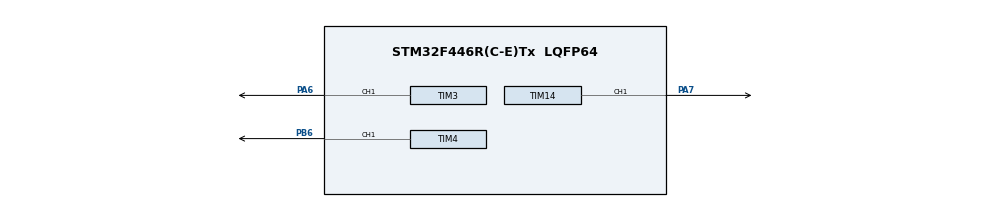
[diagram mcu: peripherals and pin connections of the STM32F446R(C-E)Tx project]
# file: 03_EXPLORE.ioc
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Mcu.Family=STM32F4
Mcu.Name=STM32F446R(C-E)Tx
Mcu.Package=LQFP64
NVIC.PriorityGroup=NVIC_PRIORITYGROUP_4
NVIC.TIM1_UP_TIM10_IRQn=true\:0\:0\:false\:false\:true\:true\:true\:true
PA6.Signal=S_TIM3_CH1
PA7.Signal=S_TIM14_CH1
PB6.Signal=S_TIM4_CH1
ProjectManager.HeapSize=0x200
ProjectManager.StackSize=0x400
ProjectManager.TargetToolchain=SW4STM32
RCC.CortexFreq_Value=16000000
RCC.USBFreq_Value=96000000
RCC.VCOOutputFreq_Value=192000000
SH.S_TIM14_CH1.0=TIM14_CH1,PWM Generation1 CH1
SH.S_TIM3_CH1.0=TIM3_CH1,PWM Generation1 CH1
SH.S_TIM4_CH1.0=TIM4_CH1,PWM Generation1 CH1
TIM1.Period=9
TIM1.Prescaler=15999
TIM14.Channel=TIM_CHANNEL_1
TIM14.Period=999
TIM14.Prescaler=159
TIM3.Channel-PWM\ Generation1\ CH1=TIM_CHANNEL_1
TIM3.Period=999
TIM3.Prescaler=159
TIM4.Channel-PWM\ Generation1\ CH1=TIM_CHANNEL_1
TIM4.Period=999
TIM4.Prescaler=159
VP_TIM14_VS_ClockSourceINT.Mode=Enable_Timer
VP_TIM1_VS_ClockSourceINT.Mode=Internal
VP_TIM3_VS_ClockSourceINT.Mode=Internal
VP_TIM4_VS_ClockSourceINT.Mode=Internal
board=custom

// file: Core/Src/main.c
/* USER CODE BEGIN Header */
/**
  ******************************************************************************
  * @file           : main.c
  * @brief          : Main program body
  ******************************************************************************
  * @attention
  *
  * Copyright (c) 2025 STMicroelectronics.
  * All rights reserved.
  *
  * This software is licensed under terms that can be found in the LICENSE file
  * in the root directory of this software component.
  * If no LICENSE file comes with this software, it is provided AS-IS.
  *
  ******************************************************************************
  */
/* USER CODE END Header */
#include "main.h"

 TIM_HandleTypeDef htim1;
TIM_HandleTypeDef htim3;
TIM_HandleTypeDef htim4;
TIM_HandleTypeDef htim14;

/* USER CODE BEGIN PV */
#define FADE_STEPS   500  // 每个颜色渐变持续 2 秒（10ms 步进 × 200）

static uint16_t fade_step = 0;
static uint8_t fade_phase = 0;  // 0: R->G, 1: G->B, 2: B->R

uint32_t pwm_arr = 1000; // 对应你设置的 Period + 1
/* USER CODE END PV */

void SystemClock_Config(void);
static void MX_GPIO_Init(void);
static void MX_TIM1_Init(void);
static void MX_TIM3_Init(void);
static void MX_TIM4_Init(void);
static void MX_TIM14_Init(void);

int main(void)
{

  /* MCU Configuration--------------------------------------------------------*/

  /* Reset of all peripherals, Initializes the Flash interface and the Systick. */
  HAL_Init();

  /* Configure the system clock */
  SystemClock_Config();

  /* Initialize all configured peripherals */
  MX_GPIO_Init();
  MX_TIM1_Init();
  MX_TIM3_Init();
  MX_TIM4_Init();
  MX_TIM14_Init();
  /* USER CODE BEGIN 2 */
  HAL_TIM_PWM_Start(&htim3, TIM_CHANNEL_1);   // PA6 - RED
  HAL_TIM_PWM_Start(&htim4, TIM_CHANNEL_1);   // PB6 - GREEN
  HAL_TIM_PWM_Start(&htim14, TIM_CHANNEL_1);  // PA7 - BLUE

  HAL_TIM_Base_Start_IT(&htim1); // 启动TIM1定时器并开启中断

  /* USER CODE END 2 */

  /* Infinite loop */
  while (1)
  {

  }
}

void SystemClock_Config(void)
{
  RCC_OscInitTypeDef RCC_OscInitStruct = {0};
  RCC_ClkInitTypeDef RCC_ClkInitStruct = {0};

  /** Configure the main internal regulator output voltage
  */
  __HAL_RCC_PWR_CLK_ENABLE();
  __HAL_PWR_VOLTAGESCALING_CONFIG(PWR_REGULATOR_VOLTAGE_SCALE3);

  /** Initializes the RCC Oscillators according to the specified parameters
  * in the RCC_OscInitTypeDef structure.
  */
  RCC_OscInitStruct.OscillatorType = RCC_OSCILLATORTYPE_HSI;
  RCC_OscInitStruct.HSIState = RCC_HSI_ON;
  RCC_OscInitStruct.HSICalibrationValue = RCC_HSICALIBRATION_DEFAULT;
  RCC_OscInitStruct.PLL.PLLState = RCC_PLL_NONE;
  if (HAL_RCC_OscConfig(&RCC_OscInitStruct) != HAL_OK)
  {
    Error_Handler();
  }

  /** Initializes the CPU, AHB and APB buses clocks
  */
  RCC_ClkInitStruct.ClockType = RCC_CLOCKTYPE_HCLK|RCC_CLOCKTYPE_SYSCLK
                              |RCC_CLOCKTYPE_PCLK1|RCC_CLOCKTYPE_PCLK2;
  RCC_ClkInitStruct.SYSCLKSource = RCC_SYSCLKSOURCE_HSI;
  RCC_ClkInitStruct.AHBCLKDivider = RCC_SYSCLK_DIV1;
  RCC_ClkInitStruct.APB1CLKDivider = RCC_HCLK_DIV1;
  RCC_ClkInitStruct.APB2CLKDivider = RCC_HCLK_DIV1;

  if (HAL_RCC_ClockConfig(&RCC_ClkInitStruct, FLASH_LATENCY_0) != HAL_OK)
  {
    Error_Handler();
  }
}

static void MX_TIM1_Init(void)
{

  TIM_ClockConfigTypeDef sClockSourceConfig = {0};
  TIM_MasterConfigTypeDef sMasterConfig = {0};

  htim1.Instance = TIM1;
  htim1.Init.Prescaler = 15999;
  htim1.Init.CounterMode = TIM_COUNTERMODE_UP;
  htim1.Init.Period = 9;
  htim1.Init.ClockDivision = TIM_CLOCKDIVISION_DIV1;
  htim1.Init.RepetitionCounter = 0;
  htim1.Init.AutoReloadPreload = TIM_AUTORELOAD_PRELOAD_DISABLE;
  if (HAL_TIM_Base_Init(&htim1) != HAL_OK)
  {
    Error_Handler();
  }
  sClockSourceConfig.ClockSource = TIM_CLOCKSOURCE_INTERNAL;
  if (HAL_TIM_ConfigClockSource(&htim1, &sClockSourceConfig) != HAL_OK)
  {
    Error_Handler();
  }
  sMasterConfig.MasterOutputTrigger = TIM_TRGO_RESET;
  sMasterConfig.MasterSlaveMode = TIM_MASTERSLAVEMODE_DISABLE;
  if (HAL_TIMEx_MasterConfigSynchronization(&htim1, &sMasterConfig) != HAL_OK)
  {
    Error_Handler();
  }

}

static void MX_TIM3_Init(void)
{

  TIM_ClockConfigTypeDef sClockSourceConfig = {0};
  TIM_MasterConfigTypeDef sMasterConfig = {0};
  TIM_OC_InitTypeDef sConfigOC = {0};

  htim3.Instance = TIM3;
  htim3.Init.Prescaler = 159;
  htim3.Init.CounterMode = TIM_COUNTERMODE_UP;
  htim3.Init.Period = 999;
  htim3.Init.ClockDivision = TIM_CLOCKDIVISION_DIV1;
  htim3.Init.AutoReloadPreload = TIM_AUTORELOAD_PRELOAD_DISABLE;
  if (HAL_TIM_Base_Init(&htim3) != HAL_OK)
  {
    Error_Handler();
  }
  sClockSourceConfig.ClockSource = TIM_CLOCKSOURCE_INTERNAL;
  if (HAL_TIM_ConfigClockSource(&htim3, &sClockSourceConfig) != HAL_OK)
  {
    Error_Handler();
  }
  if (HAL_TIM_PWM_Init(&htim3) != HAL_OK)
  {
    Error_Handler();
  }
  sMasterConfig.MasterOutputTrigger = TIM_TRGO_RESET;
  sMasterConfig.MasterSlaveMode = TIM_MASTERSLAVEMODE_DISABLE;
  if (HAL_TIMEx_MasterConfigSynchronization(&htim3, &sMasterConfig) != HAL_OK)
  {
    Error_Handler();
  }
  sConfigOC.OCMode = TIM_OCMODE_PWM1;
  sConfigOC.Pulse = 0;
  sConfigOC.OCPolarity = TIM_OCPOLARITY_HIGH;
  sConfigOC.OCFastMode = TIM_OCFAST_DISABLE;
  if (HAL_TIM_PWM_ConfigChannel(&htim3, &sConfigOC, TIM_CHANNEL_1) != HAL_OK)
  {
    Error_Handler();
  }
  HAL_TIM_MspPostInit(&htim3);

}

static void MX_TIM4_Init(void)
{

  TIM_ClockConfigTypeDef sClockSourceConfig = {0};
  TIM_MasterConfigTypeDef sMasterConfig = {0};
  TIM_OC_InitTypeDef sConfigOC = {0};

  htim4.Instance = TIM4;
  htim4.Init.Prescaler = 159;
  htim4.Init.CounterMode = TIM_COUNTERMODE_UP;
  htim4.Init.Period = 999;
  htim4.Init.ClockDivision = TIM_CLOCKDIVISION_DIV1;
  htim4.Init.AutoReloadPreload = TIM_AUTORELOAD_PRELOAD_DISABLE;
  if (HAL_TIM_Base_Init(&htim4) != HAL_OK)
  {
    Error_Handler();
  }
  sClockSourceConfig.ClockSource = TIM_CLOCKSOURCE_INTERNAL;
  if (HAL_TIM_ConfigClockSource(&htim4, &sClockSourceConfig) != HAL_OK)
  {
    Error_Handler();
  }
  if (HAL_TIM_PWM_Init(&htim4) != HAL_OK)
  {
    Error_Handler();
  }
  sMasterConfig.MasterOutputTrigger = TIM_TRGO_RESET;
  sMasterConfig.MasterSlaveMode = TIM_MASTERSLAVEMODE_DISABLE;
  if (HAL_TIMEx_MasterConfigSynchronization(&htim4, &sMasterConfig) != HAL_OK)
  {
    Error_Handler();
  }
  sConfigOC.OCMode = TIM_OCMODE_PWM1;
  sConfigOC.Pulse = 0;
  sConfigOC.OCPolarity = TIM_OCPOLARITY_HIGH;
  sConfigOC.OCFastMode = TIM_OCFAST_DISABLE;
  if (HAL_TIM_PWM_ConfigChannel(&htim4, &sConfigOC, TIM_CHANNEL_1) != HAL_OK)
  {
    Error_Handler();
  }
  HAL_TIM_MspPostInit(&htim4);

}

static void MX_TIM14_Init(void)
{

  TIM_OC_InitTypeDef sConfigOC = {0};

  htim14.Instance = TIM14;
  htim14.Init.Prescaler = 159;
  htim14.Init.CounterMode = TIM_COUNTERMODE_UP;
  htim14.Init.Period = 999;
  htim14.Init.ClockDivision = TIM_CLOCKDIVISION_DIV1;
  htim14.Init.AutoReloadPreload = TIM_AUTORELOAD_PRELOAD_DISABLE;
  if (HAL_TIM_Base_Init(&htim14) != HAL_OK)
  {
    Error_Handler();
  }
  if (HAL_TIM_PWM_Init(&htim14) != HAL_OK)
  {
    Error_Handler();
  }
  sConfigOC.OCMode = TIM_OCMODE_PWM1;
  sConfigOC.Pulse = 0;
  sConfigOC.OCPolarity = TIM_OCPOLARITY_HIGH;
  sConfigOC.OCFastMode = TIM_OCFAST_DISABLE;
  if (HAL_TIM_PWM_ConfigChannel(&htim14, &sConfigOC, TIM_CHANNEL_1) != HAL_OK)
  {
    Error_Handler();
  }
  HAL_TIM_MspPostInit(&htim14);

}

static void MX_GPIO_Init(void)
{

  /* GPIO Ports Clock Enable */
  __HAL_RCC_GPIOA_CLK_ENABLE();
  __HAL_RCC_GPIOB_CLK_ENABLE();

}

/* USER CODE BEGIN 4 */
void HAL_TIM_PeriodElapsedCallback(TIM_HandleTypeDef *htim)
{
  if (htim->Instance == TIM1) {

    uint32_t duty_in  = (fade_step * pwm_arr) / FADE_STEPS;
    uint32_t duty_out = ((FADE_STEPS - fade_step) * pwm_arr) / FADE_STEPS;

    switch (fade_phase) {
    case 0:
      __HAL_TIM_SET_COMPARE(&htim3, TIM_CHANNEL_1, duty_out);
      __HAL_TIM_SET_COMPARE(&htim4, TIM_CHANNEL_1, duty_in);
      __HAL_TIM_SET_COMPARE(&htim14, TIM_CHANNEL_1, 0);
      break;
    case 1:
      __HAL_TIM_SET_COMPARE(&htim4, TIM_CHANNEL_1, duty_out);
      __HAL_TIM_SET_COMPARE(&htim14, TIM_CHANNEL_1, duty_in);
      __HAL_TIM_SET_COMPARE(&htim3, TIM_CHANNEL_1, 0);
      break;
    case 2:
      __HAL_TIM_SET_COMPARE(&htim14, TIM_CHANNEL_1, duty_out);
      __HAL_TIM_SET_COMPARE(&htim3, TIM_CHANNEL_1, duty_in);
      __HAL_TIM_SET_COMPARE(&htim4, TIM_CHANNEL_1, 0);
      break;
    }

    if (++fade_step >= FADE_STEPS) {
      fade_step = 0;
      fade_phase = (fade_phase + 1) % 3;
    }
  }
}
/* USER CODE END 4 */

void Error_Handler(void)
{
  __disable_irq();
  while (1)
  {
  }
}
